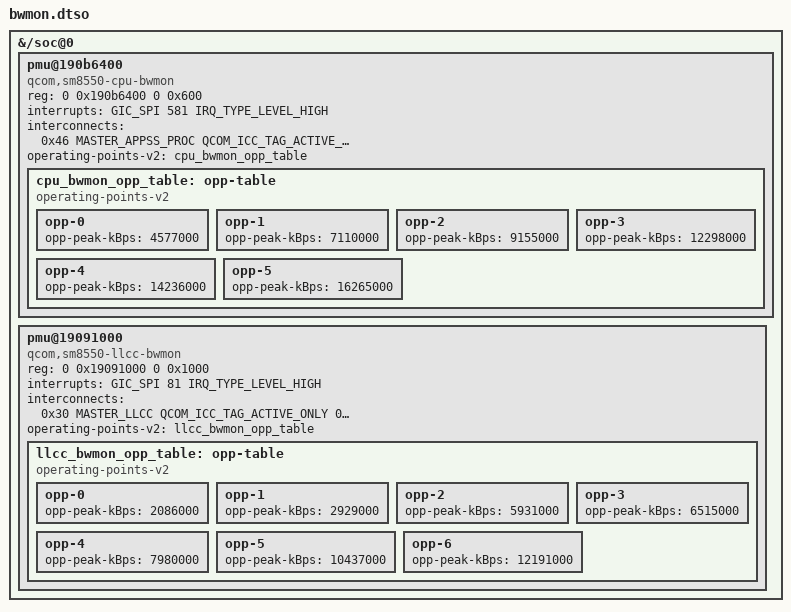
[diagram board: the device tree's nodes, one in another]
// SPDX-License-Identifier: BSD-3-Clause
/*
 * Surcouche de test : moniteurs de bande passante CPU->LLCC et LLCC->DDR du
 * SM8475 (equivalent du patch 0927), a fusionner dans le DTB installe avec
 * fdtoverlay sans reconstruire le noyau. Les phandles de gem_noc (0x46) et
 * mc_virt (0x30) sont ceux du DTB installe : verifier avec
 *   fdtget -t x <dtb> /soc@0/interconnect@19100000 phandle
 *   fdtget -t x <dtb> /interconnect-1 phandle
 */
/dts-v1/;
/plugin/;

#include <dt-bindings/interrupt-controller/arm-gic.h>
#include <dt-bindings/interconnect/qcom,icc.h>
#include <dt-bindings/interconnect/qcom,sm8450.h>

&{/soc@0} {
	pmu@190b6400 {
		compatible = "qcom,sm8550-cpu-bwmon", "qcom,sdm845-bwmon";
		reg = <0 0x190b6400 0 0x600>;
		interrupts = <GIC_SPI 581 IRQ_TYPE_LEVEL_HIGH>;
		interconnects = <0x46 MASTER_APPSS_PROC QCOM_ICC_TAG_ACTIVE_ONLY
				 0x46 SLAVE_LLCC QCOM_ICC_TAG_ACTIVE_ONLY>;

		operating-points-v2 = <&cpu_bwmon_opp_table>;

		cpu_bwmon_opp_table: opp-table {
			compatible = "operating-points-v2";

			opp-0 {
				opp-peak-kBps = <4577000>;
			};

			opp-1 {
				opp-peak-kBps = <7110000>;
			};

			opp-2 {
				opp-peak-kBps = <9155000>;
			};

			opp-3 {
				opp-peak-kBps = <12298000>;
			};

			opp-4 {
				opp-peak-kBps = <14236000>;
			};

			opp-5 {
				opp-peak-kBps = <16265000>;
			};
		};
	};

	pmu@19091000 {
		compatible = "qcom,sm8550-llcc-bwmon", "qcom,sc7280-llcc-bwmon";
		reg = <0 0x19091000 0 0x1000>;
		interrupts = <GIC_SPI 81 IRQ_TYPE_LEVEL_HIGH>;
		interconnects = <0x30 MASTER_LLCC QCOM_ICC_TAG_ACTIVE_ONLY
				 0x30 SLAVE_EBI1 QCOM_ICC_TAG_ACTIVE_ONLY>;

		operating-points-v2 = <&llcc_bwmon_opp_table>;

		llcc_bwmon_opp_table: opp-table {
			compatible = "operating-points-v2";

			opp-0 {
				opp-peak-kBps = <2086000>;
			};

			opp-1 {
				opp-peak-kBps = <2929000>;
			};

			opp-2 {
				opp-peak-kBps = <5931000>;
			};

			opp-3 {
				opp-peak-kBps = <6515000>;
			};

			opp-4 {
				opp-peak-kBps = <7980000>;
			};

			opp-5 {
				opp-peak-kBps = <10437000>;
			};

			opp-6 {
				opp-peak-kBps = <12191000>;
			};
		};
	};
};
